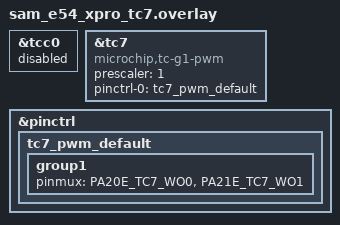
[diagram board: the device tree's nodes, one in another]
/*
 * Copyright (c) 2025 Microchip Technology Inc.
 *
 * SPDX-License-Identifier: Apache-2.0
 */

&tcc0 {
	status = "disabled";
};

&tc7 {
	compatible = "microchip,tc-g1-pwm";
	prescaler = <1>;
	#pwm-cells = <3>;
	pinctrl-0 = <&tc7_pwm_default>;
	pinctrl-names = "default";
	status = "okay";
};

&pinctrl {
	tc7_pwm_default: tc7_pwm_default {
		group1 {
			pinmux = <PA20E_TC7_WO0>,
				 <PA21E_TC7_WO1>;
		};
	};
};
